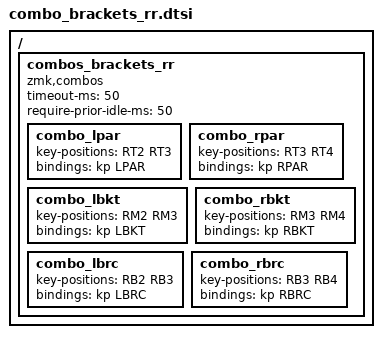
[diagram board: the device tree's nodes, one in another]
/* Corne v4 46 KEY MATRIX / LAYOUT MAPPING
╭─────────────────────────────┬─────────────────────────────╮
│ LT6 LT5 LT4 LT3 LT2 LT1 LT0 │ RT0 RT1 RT2 RT3 RT4 RT5 RT6 │
│ LM6 LM5 LM4 LM3 LM2 LM1 LM0 │ RM0 RM1 RM2 RM3 RM4 RM5 RM6 │
│ LB6 LB5 LB4 LB3 LB2 LB1     │     RB1 RB2 RB3 RB4 RB5 RB6 │
╰───--------────╮ LH2 LH1 LH0 │ RH0 RH1 RH2 ╭──────--------─╯
                ╰─────────────┴─────-───────╯ 
*/
/ {
    combos_brackets_rr {
        compatible = "zmk,combos";
        timeout-ms = <50>;
        require-prior-idle-ms = <50>;

        combo_lpar   { key-positions = <RT2 RT3>; bindings = <&kp LPAR>;   };
        combo_rpar   { key-positions = <RT3 RT4>; bindings = <&kp RPAR>;   };
        combo_lbkt   { key-positions = <RM2 RM3>; bindings = <&kp LBKT>;   };
        combo_rbkt   { key-positions = <RM3 RM4>; bindings = <&kp RBKT>;   };
        combo_lbrc   { key-positions = <RB2 RB3>; bindings = <&kp LBRC>;   };
        combo_rbrc   { key-positions = <RB3 RB4>; bindings = <&kp RBRC>;   };
    };
};

